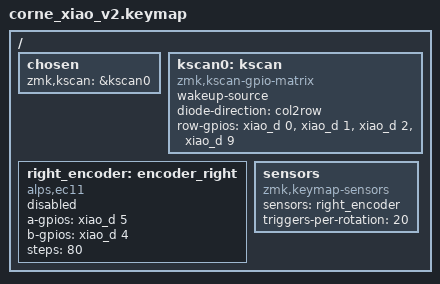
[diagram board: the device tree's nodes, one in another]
// Copyright 2022 Manna Harbour
// https://github.com/manna-harbour/miryoku

#include "../miryoku/custom_config.h"
#include "../miryoku/mapping/36/minidox.h"
#include "../miryoku/miryoku.dtsi"

/ {
    chosen {
      zmk,kscan = &kscan0;
    };

    kscan0: kscan {
      compatible = "zmk,kscan-gpio-matrix";
      wakeup-source;

      diode-direction = "col2row";
      row-gpios
        = <&xiao_d 0 (GPIO_ACTIVE_HIGH | GPIO_PULL_DOWN)>
        , <&xiao_d 1 (GPIO_ACTIVE_HIGH | GPIO_PULL_DOWN)>
        , <&xiao_d 2 (GPIO_ACTIVE_HIGH | GPIO_PULL_DOWN)>
        , <&xiao_d 9 (GPIO_ACTIVE_HIGH | GPIO_PULL_DOWN)>
        ;
    };

    right_encoder: encoder_right {
        compatible = "alps,ec11";
        a-gpios = <&xiao_d 5 (GPIO_ACTIVE_HIGH | GPIO_PULL_UP)>;
        b-gpios = <&xiao_d 4 (GPIO_ACTIVE_HIGH | GPIO_PULL_UP)>;
        steps = <80>;
        status = "disabled";
    };

    sensors: sensors {
        compatible = "zmk,keymap-sensors";
        sensors = <&right_encoder>;
        triggers-per-rotation = <20>;
    };
};

